# CEC1736_S0_2ZW register map
Vendor: Microchip Technology; Series: CEC; File version: 0
CPU: CM4 r1p0, little endian, MPU, FPU, 3 interrupt priority bits, 196 interrupts
Registers are 32-bit, read-write, reset 0x0 unless marked. A register's access mark holds for its fields unless they carry their own. Offsets are from the block's base; [hi:lo] are bit positions.

## LED0 — The LED is implemented using a PWM that can be driven either by the 48 MHz clock or by a 32.768 KHz clock input.
Base 0x4000B800; register names take the prefix LED_
Same registers: LED1 0x4000B900
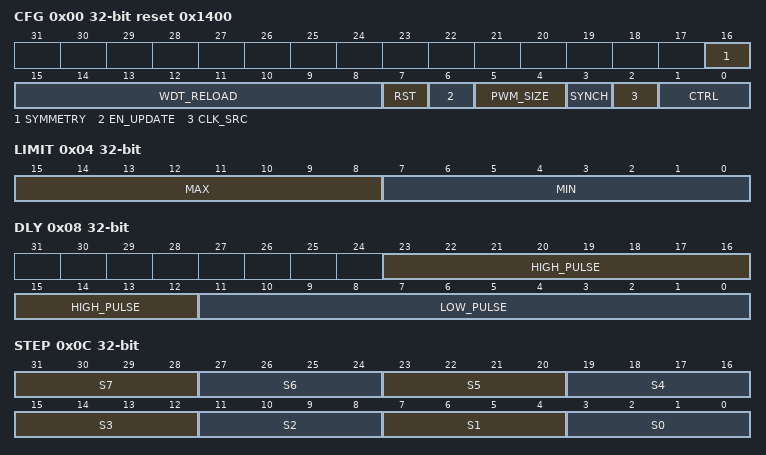
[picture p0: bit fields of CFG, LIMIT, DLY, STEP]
0x00 CFG reset 0x1400 — LED Configuration
  [16] SYMMETRY — SYMMETRY 1=The rising and falling ramp times are in Asymmetric mode. 0=The rising and falling ramp times are in Symmetric mode.
  [15:8] WDT_RELOAD — WDT_RELOAD The PWM Watchdog Timer counter reload value. On system reset, it defaults to 14h, which corresponds to a 4 second Watchdog timeout value.
  [7] RST — RESET Writes of '1' to this bit resets the PWM registers to their default values. This bit is self clearing. Writes of '0' to this bit have no effect.
  [6] EN_UPDATE — ENABLE_UPDATE This bit is set to 1 when written with a '1'. Writes of '0' have no effect. Hardware clears this bit to 0 when the breathing configuration registers are updated at the end of a PWM period. The current state of the bit is readable any time.
  [5:4] PWM_SIZE — PWM_SIZE This bit controls the behavior of PWM: 3=Reserved 2=PWM is configured as a 6-bit PWM 1=PWM is configured as a 7-bit PWM 0=PWM is configured as an 8-bit PWM
    0=PWM_SIZE_8BIT (PWM is configured as an 8-bit PWM); 1=PWM_SIZE_7BIT (PWM is configured as an 7-bit PWM); 2=PWM_SIZE_6BIT (PWM is configured as an 6-bit PWM)
  [3] SYNCH — SYNCHRONIZE When this bit is '1', all counters for all LEDs are reset to their initial values. When this bit is '0' in the LED Configuration Register for all LEDs, then all counters for LEDs that are configured to blink or breathe will increment or decrement, as required.
  [2] CLK_SRC — 1=Clock source is the 48 MHz clock, 0=Clock source is the 32.768 KHz clock
    0=LED_CLK_SRC_32KHZ (32.768 KHz clock); 1=LED_CLK_SRC_48MHZ (48 MHz clock)
  [1:0] CTRL — CONTROL 3=PWM is always on 2=LED blinking (standard PWM) 1=LED breathing configuration 0=PWM is always off. All internal registers and counters are reset to 0. Clocks are gated
    0=PWM_ALWAYS_OFF (PWM is always off); 1=LED_BREATHING; 2=LED_BLINKING; 3=PWM_ALWAYS_ON (PWM is always on)
0x04 LIMIT — LED Limits This register may be written at any time. Values written into the register are held in an holding register, which is transferred into the actual register at the end of a PWM period. The two byte fields may be written independently. Reads of this register return the current contents and not the value of the holding register.
  [15:8] MAX — In breathing mode, when the current duty cycle is greater than or equal to this value the breathing apparatus holds the current duty cycle for the period specified by the field HD in register LED_DELAY, then starts decrementing the current duty cycle
  [7:0] MIN — In breathing mode, when the current duty cycle is less than or equal to this value the breathing apparatus holds the current duty cycle for the period specified by the field LD in register LED_DELAY, then starts incrementing the current duty cycle In blinking mode, this field defines the duty cycle of the blink function.
0x08 DLY — LED Delay
  [23:12] HIGH_PULSE — In breathing mode, the number of PWM periods to wait before updating the current duty cycle when the current duty cycle is greater than or equal to the value MAX in register LED_LIMIT.
  [11:0] LOW_PULSE — The number of PWM periods to wait before updating the current duty cycle when the current duty cycle is greater than or equal to the value MIN in register LED_LIMIT.
0x0C STEP — This register has eight segment fields which provide the amount the current duty cycle is adjusted at the end of every PWM period. Segment field selection is decoded based on the segment index. The segment index equation utilized depends on the SYMMETRY bit in the LED Configuration Register Register) . In Symmetric Mode the Segment_Index[2:0] = Duty Cycle Bits[7:5] . In Asymmetric Mode the Segment_Index[2:0] is the bit concatenation of following: Segment_Index[2] = (FALLING RAMP TIME in Figure 30-3, Clipping Example) and Segment_Index[1:0] = Duty Cycle Bits[7:6].
  [31:28] S7 — Amount the current duty cycle is adjusted at the end of every PWM period when the segment index is equal to 111.
  [27:24] S6 — Amount the current duty cycle is adjusted at the end of every PWM period when the segment index is equal to 110.
  [23:20] S5 — Amount the current duty cycle is adjusted at the end of every PWM period when the segment index is equal to 101
  [19:16] S4 — Amount the current duty cycle is adjusted at the end of every PWM period when the segment index is equal to 100.
  [15:12] S3 — Amount the current duty cycle is adjusted at the end of every PWM period when the segment index is equal to 011.
  [11:8] S2 — Amount the current duty cycle is adjusted at the end of every PWM period when the segment index is equal to 010.
  [7:4] S1 — Amount the current duty cycle is adjusted at the end of every PWM period when the segment index is equal to 001.
  [3:0] S0 — Amount the current duty cycle is adjusted at the end of every PWM period when the segment index is equal to 000.
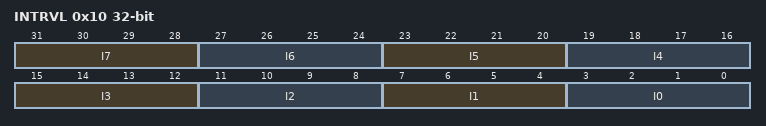
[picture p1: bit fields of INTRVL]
0x10 INTRVL — LED Update Interval
  [31:28] I7 — The number of PWM periods between updates to current duty cycle when the segment index is equal to 111b.
  [27:24] I6 — The number of PWM periods between updates to current duty cycle when the segment index is equal to 110b.
  [23:20] I5 — The number of PWM periods between updates to current duty cycle when the segment index is equal to 101b.
  [19:16] I4 — The number of PWM periods between updates to current duty cycle when the segment index is equal to 100b.
  [15:12] I3 — The number of PWM periods between updates to current duty cycle when the segment index is equal to 011b.
  [11:8] I2 — The number of PWM periods between updates to current duty cycle when the segment index is equal to 010b.
  [7:4] I1 — The number of PWM periods between updates to current duty cycle when the segment index is equal to 001b.
  [3:0] I0 — The number of PWM periods between updates to current duty cycle when the segment index is equal to 000b.
0x14 OUTDLY — LED Output Delay
  [7:0] DELAY — The delay, in counts of the clock defined in Clock Source (CLKSRC), in which output transitions are delayed. When this field is 0, there is no added transition delay. When the LED is programmed to be Always On or Always Off, the Output Delay field has no effect.

## Notices in the file
Copyright (c) 2023 Microchip Technology Inc.
SPDX-License-Identifier: Apache-2.0
Licensed under the Apache License, Version 2.0 (the "License");
you may not use this file except in compliance with the License.
You may obtain a copy of the License at
http://www.apache.org/licenses/LICENSE-2.0
Unless required by applicable law or agreed to in writing, software
distributed under the License is distributed on an "AS IS" BASIS,
WITHOUT WARRANTIES OR CONDITIONS OF ANY KIND, either express or implied.
See the License for the specific language governing permissions and
limitations under the License.
